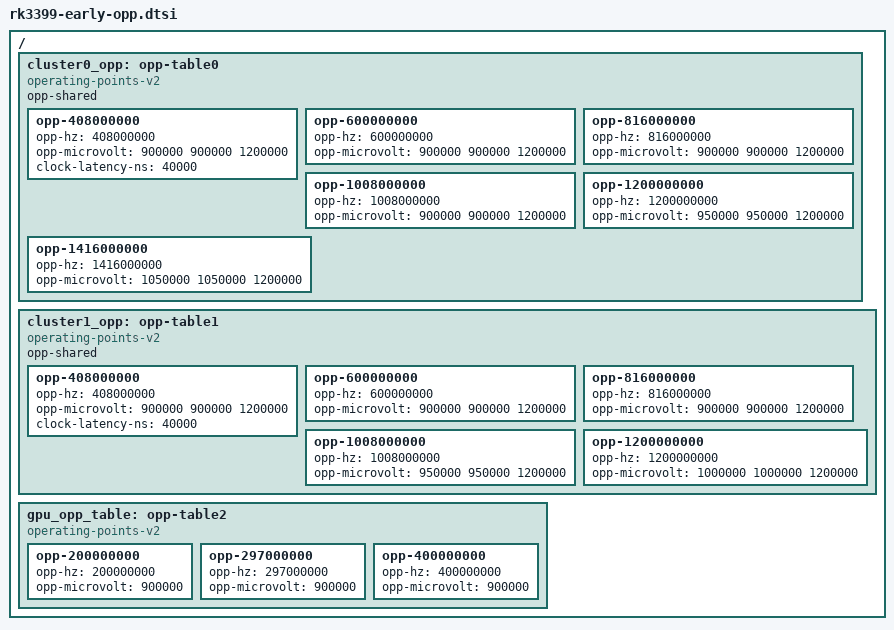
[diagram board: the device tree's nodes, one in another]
// SPDX-License-Identifier: (GPL-2.0+ OR MIT)
/*
 * Copyright (c) 2022 Rockchip Electronics Co., Ltd.
 *
 */

/*
 * NOTE: this file exists for the sake of early (pre-ES2) silicon. ES2 silicon
 * will have different power characteristics.
 */

/ {
	/delete-node/ opp-table0;
	/delete-node/ opp-table1;
	/delete-node/ opp-table2;

	cluster0_opp: opp-table0 {
		compatible = "operating-points-v2";
		opp-shared;

		opp-408000000 {
			opp-hz = /bits/ 64 <408000000>;
			opp-microvolt = <900000 900000 1200000>;
			clock-latency-ns = <40000>;
		};
		opp-600000000 {
			opp-hz = /bits/ 64 <600000000>;
			opp-microvolt = <900000 900000 1200000>;
		};
		opp-816000000 {
			opp-hz = /bits/ 64 <816000000>;
			opp-microvolt = <900000 900000 1200000>;
		};
		opp-1008000000 {
			opp-hz = /bits/ 64 <1008000000>;
			opp-microvolt = <900000 900000 1200000>;
		};
		opp-1200000000 {
			opp-hz = /bits/ 64 <1200000000>;
			opp-microvolt = <950000 950000 1200000>;
		};
		opp-1416000000 {
			opp-hz = /bits/ 64 <1416000000>;
			opp-microvolt = <1050000 1050000 1200000>;
		};
	};

	cluster1_opp: opp-table1 {
		compatible = "operating-points-v2";
		opp-shared;

		opp-408000000 {
			opp-hz = /bits/ 64 <408000000>;
			opp-microvolt = <900000 900000 1200000>;
			clock-latency-ns = <40000>;
		};
		opp-600000000 {
			opp-hz = /bits/ 64 <600000000>;
			opp-microvolt = <900000 900000 1200000>;
		};
		opp-816000000 {
			opp-hz = /bits/ 64 <816000000>;
			opp-microvolt = <900000 900000 1200000>;
		};
		opp-1008000000 {
			opp-hz = /bits/ 64 <1008000000>;
			opp-microvolt = <950000 950000 1200000>;
		};
		opp-1200000000 {
			opp-hz = /bits/ 64 <1200000000>;
			opp-microvolt = <1000000 1000000 1200000>;
		};
	};

	gpu_opp_table: opp-table2 {
		compatible = "operating-points-v2";

		opp-200000000 {
			opp-hz = /bits/ 64 <200000000>;
			opp-microvolt = <900000>;
		};
		opp-297000000 {
			opp-hz = /bits/ 64 <297000000>;
			opp-microvolt = <900000>;
		};
		opp-400000000 {
			opp-hz = /bits/ 64 <400000000>;
			opp-microvolt = <900000>;
		};
	};
};
